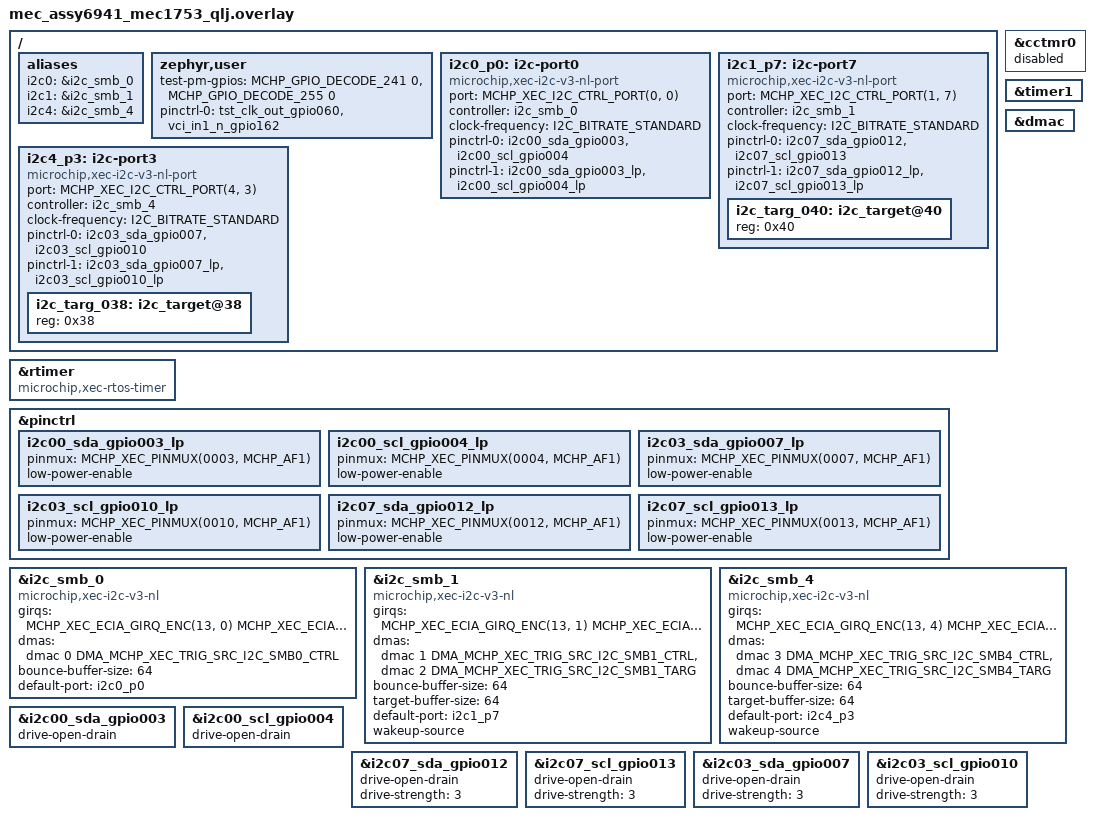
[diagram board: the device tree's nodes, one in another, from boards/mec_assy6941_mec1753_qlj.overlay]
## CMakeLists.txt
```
# Copyright (c) 2026 Microchip Technology Inc.
#
# SPDX-License-Identifier: Apache-2.0
#
cmake_minimum_required(VERSION 3.20.0)

find_package(Zephyr REQUIRED HINTS $ENV{ZEPHYR_BASE})
project(microchip_xec_pm_notifiy)

file(GLOB app_sources src/*.c)

target_sources(app PRIVATE ${app_sources})
```

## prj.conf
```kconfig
# Copyright (c) 2026 Microchip Technology Inc.
# SPDX-License-Identifier: Apache-2.0

# Console logging. Immediate mode makes log calls synchronous so the
# "entering deep sleep" line is fully flushed before the WFI, and there is
# no deferred log-processing thread that would keep the system from idling
# into the forced suspend-to-RAM state.
CONFIG_STDOUT_CONSOLE=y
CONFIG_LOG=y
CONFIG_LOG_MODE_IMMEDIATE=y

CONFIG_I2C=y
CONFIG_I2C_TARGET=y
# Buffer-mode target callbacks. Required by the NL driver's target_register
# (it rejects a target without buf_write_received); the byte-mode driver
# supports buffer mode too, so one main.c serves both boards.
CONFIG_I2C_TARGET_BUFFER_MODE=y

# Power management. CONFIG_PM enables the suspend-to-RAM (deep sleep) state
# defined on the board dts; CONFIG_PM_DEVICE gates the I2C driver's per-device
# pm_action hooks, which arm the START-detect wake on a wakeup-source target.
CONFIG_PM=y
# CONFIG_PM_DEVICE=y

CONFIG_DEBUG=y
```

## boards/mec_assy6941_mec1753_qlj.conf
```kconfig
# Copyright (c) 2026 Microchip Technology Inc.
# SPDX-License-Identifier: Apache-2.0

# I2Cv3-NL depends on DMA. Target mode uses a second DMA channel per
# controller, so the DMA driver must be enabled on the NL (qlj) build.
CONFIG_DMA=y
CONFIG_DMA_MCHP_XEC_MAX_BLOCKS_PER_CHAN=4

# debug
#CONFIG_I2C_MCHP_XEC_V3_NL_STATE_CAPTURE=y
```

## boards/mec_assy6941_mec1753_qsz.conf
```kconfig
# Copyright (c) 2026 Microchip Technology Inc.
# SPDX-License-Identifier: Apache-2.0

# debug
#CONFIG_I2C_MCHP_XEC_V3_BM_STATE_CAPTURE=y
```

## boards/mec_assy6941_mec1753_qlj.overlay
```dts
/*
 * Copyright (c) 2026 Microchip Technology Inc.
 *
 * SPDX-License-Identifier: Apache-2.0
 */

/* mec_assy6941 EVB - deep-sleep wake-on-I2C sample (I2Cv3-NL / DMA driver).
 *
 * Topology:
 *   SMB0 = controller on port 0 @ 100 kHz.
 *   SMB1 = target 0x40 on port 7 @ 100 kHz (plain, not wake-capable).
 *   SMB4 = target 0x38 on port 3 @ 100 kHz, WAKE-CAPABLE (wakeup-source).
 *
 * Set VTR2 to +3.3V, J68 2x8 1-2.
 *
 * I2C Port 0 (SMB0 controller)
 * ----------------------------
 * JP15 3x6 Pin Mux:   7-8 GPIO004 as I2C00_SCL, 4-5 GPIO003 as I2C00_SDA
 * JP27 3x12 Pin Mux:  31-32 GPIO004 as I2C00_SCL, 34-35 GPIO003 as I2C00_SDA
 * JP70 2x17 Pull-Ups: 19-20 ON, 21-22 ON (7.5K to VTR1)
 * J12 1x6: pin 1 = I2C00_SCL/GPIO004, pin 3 = I2C00_SDA/GPIO003, pin 5 = VTR1
 *
 * I2C Port 7 (SMB1 target 0x40)
 * -----------------------------
 * JP14 3x6:  7-8, 16-17
 * JP76 2x17: 21-22, 23-24 (7.5K to VTR2)
 * J22 1x6: pin 1 = I2C07_SCL/GPIO013, pin 3 = I2C07_SDA/GPIO012, pin 5 = VTR2
 *
 * Pre-sleep loopback self-test wiring (port 0 <-> port 7):
 *   Fly wire J22-1 to J12-1 (SCL) and J22-3 to J12-3 (SDA).
 *   SMB0 (port 0) drives the 0x40 target that SMB1 exposes on port 7.
 *
 * I2C Port 3 (SMB4 target 0x38, wake source)
 * ------------------------------------------
 * I2C03_SDA = GPIO007, I2C03_SCL = GPIO010.
 * Connect the EXTERNAL I2C controller here. After the SoC enters deep
 * sleep, a START + address 0x38 from that controller wakes it.
 *
 * JP11 3x6: PS2 Signal Demux
 * 7-8 jumper ON. Select I2C03_SCL for GPIO010
 * 10-11 jumper ON. Select I2C03_SDA for GPIO007
 *
 * JP29 3x8: UART-3 Signal Demux
 * 7-8 jumper ON. Select I2C03_SDA for GPIO007
 * 16-17 jumper ON. Select I2C03_SCL for GPIO010
 *
 * JP70 2x17: Pull-ups to VTR1(+3.3V)
 * 23-24 jumper ON. 7.5K pull-up on I2C03_SDA
 * 25-26 jumper ON. 7.5K pull-up on I2C03_SCL
 *
 * J15 1x6 header
 * 1 = I2C03_SCL
 * 2 = GND
 * 3 = I2C03_SDA
 * 4 = N/C
 * 5 = VTR1 (+3.3V)
 * 6 = GND
 *
 * Test pins
 * GPIO241
 * JP19 3x6 5-6
 * JP69 2x17 1-2 pull-up (100K) to VTR1
 *
 * GPIO255
 * JP24 3x16 7-8
 * JP74 2x17 29-30 pull-up (100K) to VTR1
 *
 * vci_in1_n_gpio162
 * J56 3-4 no jumper
 * J57 3-4 jumper switch S4 via schmidt trigger U19B
 * JP147 2x17 27-28 no jumper
 *
 * tst_clk_out_gpio060
 * CPU daughter card assy6949 J1 2x5 pin 1 = TST_CLK_OUT_HD, pin 3 = GND
 */

#include <zephyr/dt-bindings/gpio/microchip-xec-gpio.h>
#include <zephyr/dt-bindings/dma/mchp-xec-dmac.h>
#include <zephyr/dt-bindings/i2c/i2c.h>
#include <zephyr/dt-bindings/i2c/mchp-xec-i2c.h>

/* Enable kernel timer driver for RTOS timer plus a basic timer for k_busy_wait */
&rtimer {
	compatible = "microchip,xec-rtos-timer";
	status = "okay";
};


/* Disable CCT kernel timer driver.
 * CCT uses RTOS timer for deep sleep when the PLL is off.
 */
&cctmr0 {
	status = "disabled";
};

&timer1 {
	status = "okay";
};

/* define sleep states for I2C pins */
&pinctrl {
	i2c00_sda_gpio003_lp: i2c00_sda_gpio003_lp {
		pinmux = <MCHP_XEC_PINMUX(0003, MCHP_AF1)>;
		low-power-enable;
	};
	i2c00_scl_gpio004_lp: i2c00_scl_gpio004_lp {
		pinmux = <MCHP_XEC_PINMUX(0004, MCHP_AF1)>;
		low-power-enable;
	};
	i2c03_sda_gpio007_lp: i2c03_sda_gpio007_lp {
		pinmux = <MCHP_XEC_PINMUX(0007, MCHP_AF1)>;
		low-power-enable;
	};
	i2c03_scl_gpio010_lp: i2c03_scl_gpio010_lp {
		pinmux = <MCHP_XEC_PINMUX(0010, MCHP_AF1)>;
		low-power-enable;
	};
	i2c07_sda_gpio012_lp: i2c07_sda_gpio012_lp {
		pinmux = <MCHP_XEC_PINMUX(0012, MCHP_AF1)>;
		low-power-enable;
	};
	i2c07_scl_gpio013_lp: i2c07_scl_gpio013_lp {
		pinmux = <MCHP_XEC_PINMUX(0013, MCHP_AF1)>;
		low-power-enable;
	};
};

&dmac {
	status = "okay";
};

/* SMB0: controller only -> one "host" DMA channel. */
&i2c_smb_0 {
	compatible = "microchip,xec-i2c-v3-nl";
	status = "okay";
	#address-cells = <1>;
	#size-cells = <0>;
	girqs = <MCHP_XEC_ECIA_GIRQ_ENC(13, 0) MCHP_XEC_ECIA_GIRQ_ENC(22, 1)>;
	dmas = <&dmac 0 DMA_MCHP_XEC_TRIG_SRC_I2C_SMB0_CTRL>;
	dma-names = "host";
	bounce-buffer-size = <64>;
	default-port = <&i2c0_p0>;
};

/* SMB1: target 0x40 -> needs "host" + "target" DMA channels. */
&i2c_smb_1 {
	compatible = "microchip,xec-i2c-v3-nl";
	status = "okay";
	#address-cells = <1>;
	#size-cells = <0>;
	girqs = <MCHP_XEC_ECIA_GIRQ_ENC(13, 1) MCHP_XEC_ECIA_GIRQ_ENC(22, 2)>;
	dmas = <&dmac 1 DMA_MCHP_XEC_TRIG_SRC_I2C_SMB1_CTRL>,
	       <&dmac 2 DMA_MCHP_XEC_TRIG_SRC_I2C_SMB1_TARG>;
	dma-names = "host", "target";
	bounce-buffer-size = <64>;
	target-buffer-size = <64>;
	default-port = <&i2c1_p7>;
	wakeup-source;
};

/* SMB4: wake-capable target 0x38 -> "host" + "target" DMA channels, plus
 * wakeup-source so the driver arms START-detect wake on suspend.
 */
&i2c_smb_4 {
	compatible = "microchip,xec-i2c-v3-nl";
	status = "okay";
	#address-cells = <1>;
	#size-cells = <0>;
	girqs = <MCHP_XEC_ECIA_GIRQ_ENC(13, 4) MCHP_XEC_ECIA_GIRQ_ENC(22, 5)>;
	dmas = <&dmac 3 DMA_MCHP_XEC_TRIG_SRC_I2C_SMB4_CTRL>,
	       <&dmac 4 DMA_MCHP_XEC_TRIG_SRC_I2C_SMB4_TARG>;
	dma-names = "host", "target";
	bounce-buffer-size = <64>;
	target-buffer-size = <64>;
	default-port = <&i2c4_p3>;
	wakeup-source;
};

/* Port 0 pins */
&i2c00_sda_gpio003 {
	drive-open-drain;
};

&i2c00_scl_gpio004 {
	drive-open-drain;
};

/* Port 7 pins */
&i2c07_sda_gpio012 {
	drive-open-drain;
	drive-strength = <3>;
};

&i2c07_scl_gpio013 {
	drive-open-drain;
	drive-strength = <3>;
};

/* Port 3 pins */
&i2c03_sda_gpio007 {
	drive-open-drain;
	drive-strength = <3>;
};

&i2c03_scl_gpio010 {
	drive-open-drain;
	drive-strength = <3>;
};

/ {
	aliases {
		i2c0 = &i2c_smb_0;
		i2c1 = &i2c_smb_1;
		i2c4 = &i2c_smb_4;
	};

	/* Configure GPIO060 as test PLL clock out.
	 * We scope this pin to observe if PLL is turned off in deep sleep (suspend).
	*/
	zephyr,user {
		test-pm-gpios = <MCHP_GPIO_DECODE_241 0>, <MCHP_GPIO_DECODE_255 0>;
		pinctrl-0 = <&tst_clk_out_gpio060 &vci_in1_n_gpio162>;
		pinctrl-names = "default";
	};

	/* Port 0 on SMB0 - controller side of the loopback self-test. */
	i2c0_p0: i2c-port0 {
		compatible = "microchip,xec-i2c-v3-nl-port";
		#address-cells = <1>;
		#size-cells = <0>;
		port = <MCHP_XEC_I2C_CTRL_PORT(0, 0)>;
		controller = <&i2c_smb_0>;
		clock-frequency = <I2C_BITRATE_STANDARD>;
		pinctrl-0 = <&i2c00_sda_gpio003 &i2c00_scl_gpio004>;
		pinctrl-1 = <&i2c00_sda_gpio003_lp &i2c00_scl_gpio004_lp>;
		pinctrl-names = "default", "sleep";
		status = "okay";
	};

	/* Port 7 on SMB1 - plain target 0x40. */
	i2c1_p7: i2c-port7 {
		compatible = "microchip,xec-i2c-v3-nl-port";
		#address-cells = <1>;
		#size-cells = <0>;
		port = <MCHP_XEC_I2C_CTRL_PORT(1, 7)>;
		controller = <&i2c_smb_1>;
		clock-frequency = <I2C_BITRATE_STANDARD>;
		pinctrl-0 = <&i2c07_sda_gpio012 &i2c07_scl_gpio013>;
		pinctrl-1 = <&i2c07_sda_gpio012_lp &i2c07_scl_gpio013_lp>;
		pinctrl-names = "default", "sleep";
		status = "okay";

		i2c_targ_040: i2c_target@40 {
			reg = <0x40>;
			status = "okay";
		};
	};

	/* Port 3 on SMB4 - wake-capable target 0x38, driven by the external
	 * controller that wakes the SoC from deep sleep.
	 */
	i2c4_p3: i2c-port3 {
		compatible = "microchip,xec-i2c-v3-nl-port";
		#address-cells = <1>;
		#size-cells = <0>;
		port = <MCHP_XEC_I2C_CTRL_PORT(4, 3)>;
		controller = <&i2c_smb_4>;
		clock-frequency = <I2C_BITRATE_STANDARD>;
		pinctrl-0 = <&i2c03_sda_gpio007 &i2c03_scl_gpio010>;
		pinctrl-1 = <&i2c03_sda_gpio007_lp &i2c03_scl_gpio010_lp>;
		pinctrl-names = "default", "sleep";
		status = "okay";

		i2c_targ_038: i2c_target@38 {
			reg = <0x38>;
			status = "okay";
		};
	};
};
```

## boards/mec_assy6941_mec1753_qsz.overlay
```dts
/*
 * Copyright (c) 2026 Microchip Technology Inc.
 *
 * SPDX-License-Identifier: Apache-2.0
 */

/* mec_assy6941 EVB - deep-sleep wake-on-I2C sample (I2Cv3 byte-mode driver).
 *
 * Topology:
 *   SMB0 = controller on port 0 @ 100 kHz.
 *   SMB1 = target 0x40 on port 7 @ 100 kHz (plain, not wake-capable).
 *   SMB4 = target 0x38 on port 3 @ 100 kHz, WAKE-CAPABLE (wakeup-source).
 *
 * Set VTR2 to +3.3V, J68 2x8 1-2.
 *
 * I2C Port 0 (SMB0 controller)
 * ----------------------------
 * JP15 3x6 Pin Mux:   7-8 GPIO004 as I2C00_SCL, 4-5 GPIO003 as I2C00_SDA
 * JP27 3x12 Pin Mux:  31-32 GPIO004 as I2C00_SCL, 34-35 GPIO003 as I2C00_SDA
 * JP70 2x17 Pull-Ups: 19-20 ON, 21-22 ON (7.5K to VTR1)
 * J12 1x6: pin 1 = I2C00_SCL/GPIO004, pin 3 = I2C00_SDA/GPIO003, pin 5 = VTR1
 *
 * I2C Port 7 (SMB1 target 0x40)
 * -----------------------------
 * JP14 3x6:  7-8, 16-17
 * JP76 2x17: 21-22, 23-24 (7.5K to VTR2)
 * J22 1x6: pin 1 = I2C07_SCL/GPIO013, pin 3 = I2C07_SDA/GPIO012, pin 5 = VTR2
 *
 * Pre-sleep loopback self-test wiring (port 0 <-> port 7):
 *   Fly wire J22-1 to J12-1 (SCL) and J22-3 to J12-3 (SDA).
 *   SMB0 (port 0) drives the 0x40 target that SMB1 exposes on port 7.
 *
 * I2C Port 3 (SMB4 target 0x38, wake source)
 * ------------------------------------------
 * I2C03_SDA = GPIO007, I2C03_SCL = GPIO010.
 * Connect the EXTERNAL I2C controller here. After the SoC enters deep
 * sleep, a START + address 0x38 from that controller wakes it.
 *
 * Test pins
 * GPIO241
 * JP19 3x6 5-6
 * JP69 2x17 1-2 pull-up (100K) to VTR1
 *
 * GPIO255
 * JP24 3x16 7-8
 * JP74 2x17 29-30 pull-up (100K) to VTR1
 *
 * vci_in1_n_gpio162
 * J56 3-4 no jumper
 * J57 3-4 jumper switch S4 via schmidt trigger U19B
 * JP147 2x17 27-28 no jumper
 *
 * tst_clk_out_gpio060
 * CPU daughter card assy6949 J1 2x5 pin 1 = TST_CLK_OUT_HD, pin 3 = GND
 */

#include <zephyr/dt-bindings/gpio/microchip-xec-gpio.h>
#include <zephyr/dt-bindings/i2c/i2c.h>
#include <zephyr/dt-bindings/i2c/mchp-xec-i2c.h>

/* Use CCT as kernel timer. We need to disable RTOS timer to not load its timer driver */
&rtimer {
	status = "disabled";
}

/* Enable CCT to load its kernel timer driver.
 * CCT uses RTOS timer for deep sleep when the PLL is off.
 */
&cctmr0 {
	compatible = "microchip,xec-cct-ktimer";
	status = "okay";
};

/* define sleep states for I2C pins */
&pinctrl {
	i2c00_sda_gpio003_lp: i2c00_sda_gpio003_lp {
		pinmux = <MCHP_XEC_PINMUX(0003, MCHP_AF1)>;
		low-power-enable;
	};
	i2c00_scl_gpio004_lp: i2c00_scl_gpio004_lp {
		pinmux = <MCHP_XEC_PINMUX(0004, MCHP_AF1)>;
		low-power-enable;
	};
	i2c03_sda_gpio007_lp: i2c03_sda_gpio007_lp {
		pinmux = <MCHP_XEC_PINMUX(0007, MCHP_AF1)>;
		low-power-enable;
	};
	i2c03_scl_gpio010_lp: i2c03_scl_gpio010_lp {
		pinmux = <MCHP_XEC_PINMUX(0010, MCHP_AF1)>;
		low-power-enable;
	};
	i2c07_sda_gpio012_lp: i2c07_sda_gpio012_lp {
		pinmux = <MCHP_XEC_PINMUX(0012, MCHP_AF1)>;
		low-power-enable;
	};
	i2c07_scl_gpio013_lp: i2c07_scl_gpio013_lp {
		pinmux = <MCHP_XEC_PINMUX(0013, MCHP_AF1)>;
		low-power-enable;
	};
};

/* SMB0: controller on port 0. */
&i2c_smb_0 {
	compatible = "microchip,xec-i2c-v3-bm";
	status = "okay";
	#address-cells = <1>;
	#size-cells = <0>;
	default-port = <&i2c0_p0>;
};

/* SMB1: plain target 0x40 on port 7. */
&i2c_smb_1 {
	compatible = "microchip,xec-i2c-v3-bm";
	status = "okay";
	#address-cells = <1>;
	#size-cells = <0>;
	target-buffer-size = <64>;
	default-port = <&i2c1_p7>;
	wakeup-source;
};

/* SMB4: wake-capable target 0x38 on port 3. */
&i2c_smb_4 {
	compatible = "microchip,xec-i2c-v3-bm";
	status = "okay";
	#address-cells = <1>;
	#size-cells = <0>;
	target-buffer-size = <64>;
	default-port = <&i2c4_p3>;
	wakeup-source;
};

/* Port 0 pins */
&i2c00_sda_gpio003 {
	drive-open-drain;
};

&i2c00_scl_gpio004 {
	drive-open-drain;
};

/* Port 7 pins */
&i2c07_sda_gpio012 {
	drive-open-drain;
	drive-strength = <3>;
};

&i2c07_scl_gpio013 {
	drive-open-drain;
	drive-strength = <3>;
};

/* Port 3 pins */
&i2c03_sda_gpio007 {
	drive-open-drain;
	drive-strength = <3>;
};

&i2c03_scl_gpio010 {
	drive-open-drain;
	drive-strength = <3>;
};

/ {
	aliases {
		i2c0 = &i2c_smb_0;
		i2c1 = &i2c_smb_1;
		i2c4 = &i2c_smb_4;
	};

	/* Configure GPIO060 as test PLL clock out.
	 * We scope this pin to observe if PLL is turned off in deep sleep (suspend).
	*/
	zephyr,user {
		test-pm-gpios = <MCHP_GPIO_DECODE_241 0>, <MCHP_GPIO_DECODE_255 0>;
		pinctrl-0 = <&tst_clk_out_gpio060>;
		pinctrl-names = "default";
	};

	/* Port 0 on SMB0 - controller side of the loopback self-test. */
	i2c0_p0: i2c-port0 {
		compatible = "microchip,xec-i2c-v3-bm-port";
		#address-cells = <1>;
		#size-cells = <0>;
		port = <MCHP_XEC_I2C_CTRL_PORT(0, 0)>;
		controller = <&i2c_smb_0>;
		clock-frequency = <I2C_BITRATE_STANDARD>;
		pinctrl-0 = <&i2c00_sda_gpio003 &i2c00_scl_gpio004>;
		pinctrl-1 = <&i2c00_sda_gpio003_lp &i2c00_scl_gpio004_lp>;
		pinctrl-names = "default", "sleep";
		status = "okay";
	};

	/* Port 7 on SMB1 - plain target 0x40. */
	i2c1_p7: i2c-port7 {
		compatible = "microchip,xec-i2c-v3-bm-port";
		#address-cells = <1>;
		#size-cells = <0>;
		port = <MCHP_XEC_I2C_CTRL_PORT(1, 7)>;
		controller = <&i2c_smb_1>;
		clock-frequency = <I2C_BITRATE_STANDARD>;
		pinctrl-0 = <&i2c07_sda_gpio012 &i2c07_scl_gpio013>;
		pinctrl-1 = <&i2c07_sda_gpio012_lp &i2c07_scl_gpio013_lp>;
		pinctrl-names = "default", "sleep";
		status = "okay";

		i2c_targ_040: i2c_target@40 {
			reg = <0x40>;
			status = "okay";
		};
	};

	/* Port 3 on SMB4 - wake-capable target 0x38, driven by the external
	 * controller that wakes the SoC from deep sleep.
	 */
	i2c4_p3: i2c-port3 {
		compatible = "microchip,xec-i2c-v3-bm-port";
		#address-cells = <1>;
		#size-cells = <0>;
		port = <MCHP_XEC_I2C_CTRL_PORT(4, 3)>;
		controller = <&i2c_smb_4>;
		clock-frequency = <I2C_BITRATE_STANDARD>;
		pinctrl-0 = <&i2c03_sda_gpio007 &i2c03_scl_gpio010>;
		pinctrl-1 = <&i2c03_sda_gpio007_lp &i2c03_scl_gpio010_lp>;
		pinctrl-names = "default", "sleep";
		status = "okay";

		i2c_targ_038: i2c_target@38 {
			reg = <0x38>;
			status = "okay";
		};
	};
};
```

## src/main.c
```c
/*
 * Copyright (c) 2026 Microchip Technology Inc.
 *
 * SPDX-License-Identifier: Apache-2.0
 */

/*
 * I2Cv3 deep-sleep wake-on-I2C sample.
 *
 * Demonstrates waking the MEC1753 SoC from deep sleep (suspend-to-RAM)
 * when an external I2C controller addresses a registered, wake-capable
 * target. The board overlay selects the driver:
 *   mec1753_qlj -> microchip,xec-i2c-v3-nl (network-layer / DMA)
 *   mec1753_qsz -> microchip,xec-i2c-v3-bm (byte-mode)
 *
 * Topology (both boards):
 *   SMB0 = controller on port 0 @ 100 kHz.
 *   SMB1 = plain target 0x40 on port 7 @ 100 kHz.
 *   SMB4 = wake-capable target 0x38 on port 3 @ 100 kHz (wakeup-source).
 *
 * Flow:
 *   1. Register the 0x40 and 0x38 targets.
 *   2. Pre-sleep loopback self-test: with port 0 fly-wired to port 7
 *      (J12 <-> J22), SMB0 writes then reads back the 0x40 target to
 *      prove the controller + target paths work.
 *   3. Force PM_STATE_SUSPEND_TO_RAM (deep sleep) and block waiting for
 *      the 0x38 target's stop callback.
 *   4. An external I2C controller on port 3 issues START + address 0x38,
 *      which wakes the SoC. The target callbacks capture the bytes; the
 *      app logs them (proving the wake source) and halts.
 *
 * Wake requires ALL of: CONFIG_PM_DEVICE, CONFIG_I2C_TARGET, wakeup-source
 * on the SMB4 controller node, and a registered target on it -- only then
 * does the driver's suspend hook arm the START-detect wake.
 */

#include <string.h>
#include <zephyr/kernel.h>
#include <zephyr/device.h>
#include <zephyr/devicetree.h>
#include <zephyr/drivers/gpio.h>
#include <zephyr/drivers/i2c.h>
#include <zephyr/drivers/i2c/mchp_xec_i2c.h>
#include <zephyr/drivers/pinctrl.h>
#include <zephyr/dt-bindings/i2c/i2c.h>
#include <zephyr/dt-bindings/interrupt-controller/mchp-xec-ecia.h>
#include <zephyr/logging/log.h>
#include <zephyr/logging/log_ctrl.h>
#include <zephyr/pm/pm.h>
#include <zephyr/pm/device.h>

#include "pm_app.h"
#include "xec_vci.h"

LOG_MODULE_REGISTER(app, CONFIG_LOG_DEFAULT_LEVEL);

/* Compile-time label for whichever driver the board overlay enabled. */
#if DT_NODE_HAS_COMPAT(DT_NODELABEL(i2c_smb_0), microchip_xec_i2c_v3_nl)
#define DRV_LABEL "microchip,xec-i2c-v3-nl (network-layer/DMA)"
#else
#define DRV_LABEL "microchip,xec-i2c-v3-bm (byte-mode)"
#endif

#define ZEPHYR_USER_NODE DT_PATH(zephyr_user)

PINCTRL_DT_DEFINE(ZEPHYR_USER_NODE);

/* SMB0 port-0 device: the controller bus for the loopback self-test. */
static const struct device *const smb0_port0 = DEVICE_DT_GET(DT_NODELABEL(i2c0_p0));

/* Target specs: .bus is the owning port device, .addr the 7-bit address. */
static const struct i2c_dt_spec targ040 = I2C_DT_SPEC_GET(DT_NODELABEL(i2c_targ_040));

#if DT_NODE_HAS_STATUS_OKAY(DT_NODELABEL(i2c_targ_038))
static const struct i2c_dt_spec targ038 = I2C_DT_SPEC_GET(DT_NODELABEL(i2c_targ_038));
#endif

#define APP_TARG_BUF_SIZE 64U

/* Bounded wait for the loopback target's stop; a wiring fault then surfaces
 * as a FAIL instead of a hang. The deep-sleep wait is unbounded on purpose.
 */
#define LOOPBACK_TIMEOUT K_MSEC(500)

/* Per-target application state. The buffer-mode callbacks resolve their
 * instance from the embedded i2c_target_config via CONTAINER_OF, so one
 * callback table serves both targets.
 */
struct app_target {
	const char *name;
	uint8_t buf[APP_TARG_BUF_SIZE];
	volatile size_t rx_len;      /* bytes stored by buf_write_received */
	volatile uint32_t wr_cnt;    /* buf_write_received invocations */
	volatile uint32_t rd_cnt;    /* buf_read_requested invocations */
	volatile uint32_t stop_cnt;  /* stop invocations */
	volatile uint32_t err_cnt;   /* error invocations */
	struct k_sem stop_sem;
	struct i2c_target_config cfg;
};

static struct app_target t040 = {.name = "0x40"};
#if DT_NODE_HAS_STATUS_OKAY(DT_NODELABEL(i2c_targ_038))
static struct app_target t038 = {.name = "0x38 (wake)"};
#endif

static const struct gpio_dt_spec pm_gpio_pin = GPIO_DT_SPEC_GET(ZEPHYR_USER_NODE, test_pm_gpios);

uint8_t i2c_state_cap_buf[256] __aligned(4);

static void app_buf_wr_recv(struct i2c_target_config *config, uint8_t *ptr, uint32_t len)
{
	struct app_target *t = CONTAINER_OF(config, struct app_target, cfg);
	size_t off = t->rx_len;

	t->wr_cnt++;
	if (ptr == NULL) {
		return;
	}
	for (uint32_t i = 0; (i < len) && (off < sizeof(t->buf)); i++) {
		t->buf[off++] = ptr[i];
	}
	t->rx_len = off;
}

static int app_buf_rd_req(struct i2c_target_config *config, uint8_t **ptr, uint32_t *len)
{
	struct app_target *t = CONTAINER_OF(config, struct app_target, cfg);

	t->rd_cnt++;
	if ((ptr == NULL) || (len == NULL)) {
		return -EINVAL;
	}
	*ptr = t->buf;
	*len = sizeof(t->buf);

	return 0;
}

static int app_stop(struct i2c_target_config *config)
{
	struct app_target *t = CONTAINER_OF(config, struct app_target, cfg);

	t->stop_cnt++;
	k_sem_give(&t->stop_sem);

	return 0;
}

static void app_error(struct i2c_target_config *config, enum i2c_error_reason reason)
{
	struct app_target *t = CONTAINER_OF(config, struct app_target, cfg);

	ARG_UNUSED(reason);
	t->err_cnt++;
}

static const struct i2c_target_callbacks app_callbacks = {
	.buf_write_received = app_buf_wr_recv,
	.buf_read_requested = app_buf_rd_req,
	.stop = app_stop,
	.error = app_error,
};

static void reset_target(struct app_target *t)
{
	t->rx_len = 0;
	t->wr_cnt = 0;
	t->rd_cnt = 0;
	t->stop_cnt = 0;
	t->err_cnt = 0;
	memset(t->buf, 0, sizeof(t->buf));
	k_sem_reset(&t->stop_sem);
}

static int register_target(const struct i2c_dt_spec *spec, struct app_target *t)
{
	int rc;

	k_sem_init(&t->stop_sem, 0, 1);
	reset_target(t);

	t->cfg.flags = 0;
	t->cfg.address = spec->addr;
	t->cfg.callbacks = &app_callbacks;

	LOG_INF("Register target %s (0x%02x) on %s", t->name, spec->addr, spec->bus->name);
	rc = i2c_target_register(spec->bus, &t->cfg);
	if (rc != 0) {
		LOG_ERR("i2c_target_register %s failed (%d)", t->name, rc);
	}

	return rc;
}

/* Pre-sleep loopback self-test: SMB0 (port 0) writes 4 bytes to the 0x40
 * target that SMB1 exposes on port 7 (fly-wired), then reads them back.
 * Returns 0 on PASS. Requires the J12<->J22 fly wire.
 */
static int loopback_self_test(void)
{
	static const uint8_t tx[4] = {0xDEU, 0xADU, 0xBEU, 0xEFU};
	uint8_t rx[4] = {0};
	int rc;

	reset_target(&t040);

	rc = i2c_write(smb0_port0, tx, sizeof(tx), targ040.addr);
	if (rc != 0) {
		LOG_ERR("loopback: i2c_write to 0x%02x failed (%d) - check J12<->J22 fly wire",
			targ040.addr, rc);
		return rc;
	}

	rc = k_sem_take(&t040.stop_sem, LOOPBACK_TIMEOUT);
	if (rc != 0) {
		LOG_ERR("loopback: no stop from 0x%02x target (%d)", targ040.addr, rc);
		return rc;
	}

	if ((t040.wr_cnt != 1U) || (t040.rx_len != sizeof(tx)) ||
	    (memcmp(t040.buf, tx, sizeof(tx)) != 0)) {
		LOG_ERR("loopback: write mismatch wr_cnt=%u rx_len=%u", t040.wr_cnt,
			(unsigned int)t040.rx_len);
		return -EIO;
	}

	/* Read the same bytes back over the wire. */
	rc = i2c_read(smb0_port0, rx, sizeof(rx), targ040.addr);
	if (rc != 0) {
		LOG_ERR("loopback: i2c_read from 0x%02x failed (%d)", targ040.addr, rc);
		return rc;
	}
	if (memcmp(rx, tx, sizeof(tx)) != 0) {
		LOG_ERR("loopback: read-back mismatch");
		return -EIO;
	}

	LOG_INF("loopback self-test PASS: wrote/read {%02x %02x %02x %02x} via 0x%02x",
		rx[0], rx[1], rx[2], rx[3], targ040.addr);

	return 0;
}

static void pr_pcr_clk_req_from_vbat(void)
{
	uintptr_t vbmem_addr = (uintptr_t)DT_REG_ADDR(DT_NODELABEL(bbram));

	for (uint32_t i = 0; i < 5U; i++) {
		LOG_INF("PCR CLK_REQ[%u] = 0x%08x", i, sys_read32(vbmem_addr));
		vbmem_addr += 4U;
	}
}

#if 0
extern uint32_t soc_pcr_clk_req[5];

static void pr_pcr_clk_req_wait(void)
{
	for (uint32_t i = 0; i < 5U; i++) {
		LOG_INF("PCR CLK_REQ_wait[%u] = 0x%08x", i, soc_pcr_clk_req[i]);
	}
}
#endif

int main(void)
{
	const struct pinctrl_dev_config *zu_pcfg = PINCTRL_DT_DEV_CONFIG_GET(ZEPHYR_USER_NODE);
	uint32_t r = 0;
	int rc;

	app_register_pm_notifier();

	LOG_INF("I2Cv3 deep-sleep wake sample; driver: %s", DRV_LABEL);

#ifdef CONFIG_BOARD_QUALIFIERS
	LOG_INF("Board: %s/%s", CONFIG_BOARD, CONFIG_BOARD_QUALIFIERS);
#else
	LOG_INF("Board: %s", CONFIG_BOARD);
#endif

	memset(i2c_state_cap_buf, 0, sizeof(i2c_state_cap_buf));

	if (!gpio_is_ready_dt(&pm_gpio_pin)) {
		LOG_ERR("PM GPIO pin is not ready!");
	}

	rc = gpio_pin_configure_dt(&pm_gpio_pin, GPIO_OUTPUT_HIGH);
	if (rc != 0) {
		LOG_ERR("PM GPIO pin configuration error (%d)", rc);
	}

	rc = pinctrl_apply_state(zu_pcfg, PINCTRL_STATE_DEFAULT);
	if (rc != 0) {
		LOG_ERR("Failed to configure zephyr-user pins (%d)", rc);
	}

#if DT_NODE_HAS_STATUS_OKAY(DT_NODELABEL(i2c_targ_038))
	if (!device_is_ready(smb0_port0) || !device_is_ready(targ040.bus) ||
	    !device_is_ready(targ038.bus)) {
#else
	if (!device_is_ready(smb0_port0) || !device_is_ready(targ040.bus)) {
#endif
		LOG_ERR("I2C bus device(s) not ready");
		return 0;
	}

	/* Register both targets. The 0x38 target is on the wakeup-source SMB4
	 * controller, so registering it arms the deep-sleep wake path.
	 */
	if (register_target(&targ040, &t040) != 0) {
		return 0;
	}
#if DT_NODE_HAS_STATUS_OKAY(DT_NODELABEL(i2c_targ_038))
	if (register_target(&targ038, &t038) != 0) {
		return 0;
	}
#endif

	/* Phase 1: prove the controller + target paths before sleeping. */
	rc = loopback_self_test();
	if (rc != 0) {
		LOG_WRN("loopback self-test FAILED (%d); continuing to deep-sleep demo", rc);
	}

	mchp_vci_in_input_enable(BIT(MEC_VCI_IN1_POS));
	mchp_vci_in_latch_enable(BIT(MEC_VCI_IN1_POS));
	mchp_vci_edge_detect_clr_all();
	mchp_vci_in_latch_reset(BIT(MEC_VCI_IN1_POS));

	printk("Disconnect Debugger and press switch S4 when ready");
	r = mchp_vci_pedge_detect() & mchp_vci_nedge_detect();
	while ((r & BIT(MEC_VCI_IN1_POS)) == 0) {
		r = mchp_vci_pedge_detect() & mchp_vci_nedge_detect();
	}

#if DT_NODE_HAS_STATUS_OKAY(DT_NODELABEL(i2c_targ_038))
#if defined(CONFIG_PM) || defined(CONFIG_PM_DEVICE)
	/* Phase 2: force deep sleep and wait for an external wake on 0x38. */
	reset_target(&t038);

	LOG_INF("Forcing deep sleep (PM_STATE_SUSPEND_TO_RAM).");
	LOG_INF("Wake it: drive START + address 0x%02x from an external I2C", targ038.addr);
	LOG_INF("controller on port 3 (SDA=GPIO007, SCL=GPIO010).");

	/* Force the deepest state on next idle. Blocking on the wake semaphore
	 * lets the idle thread run and enter suspend-to-RAM; the external write
	 * to 0x38 wakes the CPU (own-address match, GIRQ13), the driver runs the
	 * target callbacks, and app_stop() gives the semaphore below.
	 */
	if (!pm_state_force(0U, &(struct pm_state_info){PM_STATE_SUSPEND_TO_RAM, 0, 0})) {
		LOG_ERR("pm_state_force(SUSPEND_TO_RAM) rejected");
		return 0;
	}

	k_sem_take(&t038.stop_sem, K_FOREVER);

	/* Woke. */
	LOG_INF("WOKE from deep sleep via target 0x%02x: wr_cnt=%u rd_cnt=%u rx_len=%u",
		targ038.addr, t038.wr_cnt, t038.rd_cnt, (unsigned int)t038.rx_len);
	if (t038.rx_len > 0U) {
		LOG_HEXDUMP_INF(t038.buf, t038.rx_len, "bytes received from external controller:");
	}

	LOG_INF("PCR CLK_REQ captured just before WFI");
	pr_pcr_clk_req_from_vbat();
	/* pr_pcr_clk_req_wait(); */

#if DT_NODE_HAS_COMPAT(DT_NODELABEL(i2c_smb_4), microchip_xec_i2c_v3_nl)
#ifdef CONFIG_I2C_MCHP_XEC_V3_NL_STATE_CAPTURE
	rc = mchp_xec_i2c_nl_copy_capture(targ038.bus, i2c_state_cap_buf, 256U);
#endif
#else
#ifdef CONFIG_I2C_MCHP_XEC_V3_BM_STATE_CAPTURE
	rc = mchp_xec_i2c_bm_copy_capture(targ038.bus, i2c_state_cap_buf, 256U);
#endif
#endif
	if (rc == 0) {
		LOG_HEXDUMP_INF(i2c_state_cap_buf, 256U, "targ038.bus states");
	} else {
		LOG_ERR("I2C BM state capture copy error (%d)", rc);
	}
#endif
#endif
	LOG_INF("Deep-sleep I2C wake demo complete; halting.");
	log_flush();

	k_sleep(K_FOREVER);

	return 0;
}
```

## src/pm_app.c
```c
/*
 * Copyright (c) 2026 Microchip Technology Inc.
 *
 * SPDX-License-Identifier: Apache-2.0
 */


#include <string.h>
#include <zephyr/kernel.h>
#include <zephyr/device.h>
#include <zephyr/devicetree.h>
#include <zephyr/drivers/gpio.h>
#include <zephyr/drivers/i2c.h>
#include <zephyr/drivers/i2c/mchp_xec_i2c.h>
#include <zephyr/drivers/pinctrl.h>
#include <zephyr/dt-bindings/i2c/i2c.h>
#include <zephyr/dt-bindings/interrupt-controller/mchp-xec-ecia.h>
#include <zephyr/logging/log.h>
#include <zephyr/logging/log_ctrl.h>
#include <zephyr/pm/pm.h>
#include <zephyr/pm/device.h>

#include "xec_vci.h"

LOG_MODULE_DECLARE(app, CONFIG_LOG_DEFAULT_LEVEL);

/* ---- PM Notifier ---- */

struct app_i2c_info {
	uintptr_t reg_base;
	bool is_wake_device;
	uint8_t girq_wake;
	uint8_t girq_wake_pos;
};

struct app_uart_info {
	uintptr_t reg_base;
};

struct app_btmr_info {
	uintptr_t reg_base;
};

/* XEC Basic timers do not obey their PCR SLP_EN signal and automatically clear their CLK_REQ
 * signal. Software must save/clear/restore each basic timer's enable bit in the control register.
 * We could iterate over DT compatible but that assumes the application is using the known
 * drivers. If the application is using the HW directly and leaves it enabled then the PCR HW
 * will not disable the PLL in deep sleep.
 * There are two drivers we must check:
 * Zephyr kernel timer driver: microchip_xec_rtos_timer
 *   This driver uses one of the 32-bit basic timers for k_busy_wait. The basic timer is specified
 *   by phandle property busy_wait_timer.
 *
 * Zephyr counter driver: microchip_xec_timer
 */
#define XEC_BASIC_TMR_CR_OFS    0x10U
#define XEC_BASIC_TMR_CR_EN_POS 0

#define XEC_BTMR_COUNTER_CNT DT_NUM_INST_STATUS_OKAY(microchip_xec_timer)
#define XEC_BTMR_KT_CNT      DT_NUM_INST_STATUS_OKAY(microchip_xec_rtos_timer)

#define XEC_BTMR_TOTAL_CNT (XEC_BTMR_COUNTER_CNT + XEC_BTMR_KT_CNT)

#define XEC_BT_APP_INFO(node_id) { .reg_base = (uintptr_t)DT_REG_ADDR(node_id), },

#define XEC_RT_BWT_INFO(rt_node_id) \
	{ .reg_base = (uintptr_t)DT_REG_ADDR(DT_PHANDLE(rt_node_id, busy_wait_timer)), },

#if 0
const struct app_btmr_info app_btmr_info_table[] = {
	DT_FOREACH_STATUS_OKAY(microchip_xec_timer, XEC_BT_APP_INFO)
	DT_FOREACH_STATUS_OKAY(microchip_xec_rtos_timer, XEC_RT_BWT_INFO)
};
#else
const struct app_btmr_info app_btmr_info_table[] = {
	DT_FOREACH_STATUS_OKAY(microchip_xec_timer, XEC_BT_APP_INFO)
};
#endif

static uint8_t app_btmr_pm_save[XEC_BTMR_TOTAL_CNT];

static void xec_btmrs_pm_deep_sleep(bool enter_ds)
{
	for (uint32_t i = 0; i < ARRAY_SIZE(app_btmr_info_table); i++) {
		const struct app_btmr_info *p = &app_btmr_info_table[i];
		uint32_t cr = sys_read32(p->reg_base + XEC_BASIC_TMR_CR_OFS);

		if (enter_ds) {
			app_btmr_pm_save[i] = (uint8_t)(cr & BIT(XEC_BASIC_TMR_CR_EN_POS));
			sys_write32(cr & (uint32_t)~BIT(XEC_BASIC_TMR_CR_EN_POS),
				    p->reg_base + XEC_BASIC_TMR_CR_OFS);
		} else {
			cr |= (app_btmr_pm_save[i] & BIT(XEC_BASIC_TMR_CR_EN_POS));
			sys_write32(cr, p->reg_base + XEC_BASIC_TMR_CR_OFS);
		}
	}
}

#define XEC_I2C_V3_BM_CNT DT_NUM_INST_STATUS_OKAY(microchip_xec_i2c_v3_bm)
#define XEC_I2C_V3_NL_CNT DT_NUM_INST_STATUS_OKAY(microchip_xec_i2c_v3_nl)

#define XEC_I2C_V3_CNT (XEC_I2C_V3_BM_CNT + XEC_I2C_V3_NL_CNT)

#define XEC_I2C_GIRQ(nid) MCHP_XEC_ECIA_GIRQ(DT_PROP_BY_IDX(nid, girqs, 1))

#define XEC_I2C_GIRQ_POS(nid) MCHP_XEC_ECIA_GIRQ_POS(DT_PROP_BY_IDX(nid, girqs, 1))

#define XEC_I2C_V3_BM_APP_INFO(nid) \
	{ .reg_base = DT_REG_ADDR(nid), \
	  .is_wake_device = DT_PROP(nid, wakeup_source), \
	  .girq_wake = XEC_I2C_GIRQ(nid), \
	  .girq_wake_pos = XEC_I2C_GIRQ_POS(nid), \
	},

#define XEC_I2C_V3_NL_APP_INFO(nid) \
	{ .reg_base = DT_REG_ADDR(nid), \
	  .is_wake_device = DT_PROP(nid, wakeup_source), \
	  .girq_wake = XEC_I2C_GIRQ(nid), \
	  .girq_wake_pos = XEC_I2C_GIRQ_POS(nid), \
	},

const struct app_i2c_info app_i2c_info_table[] = {
	DT_FOREACH_STATUS_OKAY(microchip_xec_i2c_v3_bm, XEC_I2C_V3_BM_APP_INFO)
	DT_FOREACH_STATUS_OKAY(microchip_xec_i2c_v3_nl, XEC_I2C_V3_NL_APP_INFO)
};

static uint8_t app_i2c_save[XEC_I2C_V3_CNT];

static void xec_i2c_pm_deep_sleep(bool enter_ds)
{
	for (uint32_t n = 0; n < ARRAY_SIZE(app_i2c_info_table); n++) {
		const struct app_i2c_info *p = &app_i2c_info_table[n];

		if (p->is_wake_device) {
			if (enter_ds) {
				soc_i2c_wake_prepare(p->reg_base, p->girq_wake, p->girq_wake_pos);
			} else {
				soc_i2c_wake_clear(p->reg_base, p->girq_wake, p->girq_wake_pos);
			}
		} else {
			if (enter_ds) {
				app_i2c_save[n] = soc_i2c_get_enable(p->reg_base);
				soc_i2c_set_enable(p->reg_base, 0);
			} else {
				soc_i2c_set_enable(p->reg_base, app_i2c_save[n]);
			}
		}
	}
}

/* --- garbage eSPI v2 driver ----
 * If eSPI enabled we configure its PLL wake GIRQ22 on deep sleep entry.
 */
#define XEC_ESPI_NODE DT_NODELABEL(espi0)

#define XEC_ESPI_WK_GIRQ(node_id)     MCHP_XEC_ECIA_GIRQ_POS(DT_PROP_BY_IDX(node_id, girqs, 11))
#define XEC_ESPI_WK_GIRQ_POS(node_id) MCHP_XEC_ECIA_GIRQ_POS(DT_PROP_BY_IDX(node_id, girqs, 11))

static void xec_espi_pm_deep_sleep(bool enter_ds)
{
#if DT_HAS_COMPAT_STATUS_OKAY(microchip_xec_espi_v2)
	uint8_t girq_wake = XEC_ESPI_WK_GIRQ(XEC_ESPI_NODE);
	uint8_t girq_wake_pos = XEC_ESPI_WK_GIRQ_POS(XEC_ESPI_NODE);
	uint8_t enable = (enter_ds) ? 1U : 0;

	soc_ecia_girq_status_clear(girq_wake, girq_wake_pos);
	soc_ecia_girq_ctrl(girq_wake, girq_wake_pos, enable);
#endif
}

/* --- UART ---
 * XEC UART does not obey PCR SLP_EN assertion. If the UART is enabled it asserts its CLK_REQ
 * signal. We must clear the activate bit in each UART the application is using.
 */
#define XEC_UART_ACTIVATE_REG_OFS 0x330U

#define XEC_UART_APP_CNT DT_NUM_INST_STATUS_OKAY(microchip_xec_uart)

#define XEC_UART_APP_INFO(node_id) { .reg_base = (uintptr_t)DT_REG_ADDR(node_id), },

const struct app_uart_info app_uart_info_table[] = {
	DT_FOREACH_STATUS_OKAY(microchip_xec_uart, XEC_UART_APP_INFO)
};

static uint8_t app_uart_pm_save[XEC_UART_APP_CNT];

static void xec_uart_pm_deep_sleep(bool enter_ds)
{
	for (uint32_t i = 0; i < ARRAY_SIZE(app_uart_info_table); i++) {
		const struct app_uart_info *p = &app_uart_info_table[i];

		if (enter_ds) {
			app_uart_pm_save[i] = sys_read8(p->reg_base + XEC_UART_ACTIVATE_REG_OFS);
			sys_write8(0, p->reg_base + XEC_UART_ACTIVATE_REG_OFS);
		} else {
			sys_write8(app_uart_pm_save[i], p->reg_base + XEC_UART_ACTIVATE_REG_OFS);
		}
	}
}

static void xec_i3c_pm_deep_sleep(bool enter_ds)
{
	/* TODO when I3C driver is available */
}

static void xec_spi_target_pm_deep_sleep(bool enter_ds)
{
	/* TODO when SPI target driver is available */
}

/* Interrupts are locked when PM subsystem calls this */
static void app_pm_entry(enum pm_state state_to_enter)
{
	if (state_to_enter == PM_STATE_SUSPEND_TO_RAM) { /* enter deep sleep */
		xec_btmrs_pm_deep_sleep(true);
		xec_i2c_pm_deep_sleep(true);
		xec_espi_pm_deep_sleep(true);
		xec_i3c_pm_deep_sleep(true);
		xec_spi_target_pm_deep_sleep(true);
		xec_uart_pm_deep_sleep(true);
	}
}

static void app_pm_exit(enum pm_state state_exit_from)
{
	if (state_exit_from == PM_STATE_SUSPEND_TO_RAM) { /* exit deep sleep */
		xec_btmrs_pm_deep_sleep(false);
		xec_i2c_pm_deep_sleep(false);
		xec_espi_pm_deep_sleep(false);
		xec_i3c_pm_deep_sleep(false);
		xec_spi_target_pm_deep_sleep(false);
		xec_uart_pm_deep_sleep(false);
	}
}

static struct pm_notifier app_pm_notifier = {
	.state_entry = app_pm_entry,
	.state_exit = app_pm_exit,
	.report_substate = false,
};

void app_register_pm_notifier(void)
{
	LOG_INF("Register App PM notifier");
	pm_notifier_register(&app_pm_notifier);
}
```

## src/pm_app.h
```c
/*
 * Copyright (c) 2026 Microchip Technology Inc.
 *
 * SPDX-License-Identifier: Apache-2.0
 */

#ifndef _XEC_PM_NOTIFY_PM_APP_H
#define _XEC_PM_NOTIFY_PM_APP_H

#include <stdint.h>

void app_register_pm_notifier(void);

#endif /* _XEC_PM_NOTIFY_PM_APP_H */
```
